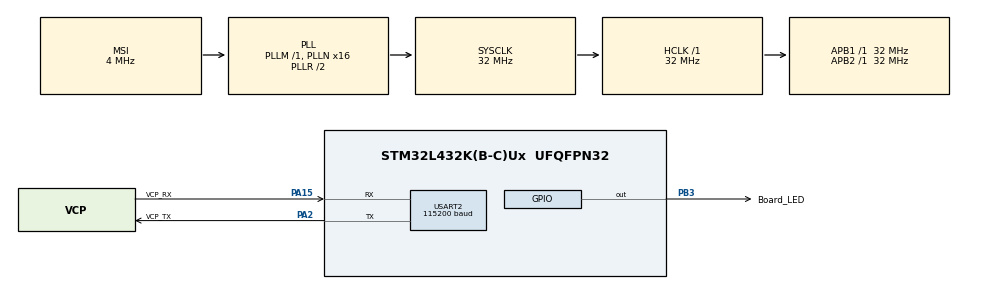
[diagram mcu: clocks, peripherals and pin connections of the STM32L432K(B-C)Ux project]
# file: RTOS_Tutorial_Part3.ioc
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FREERTOS.Tasks01=UART_task,24,128,UARTThread,Default,NULL,Dynamic,NULL,NULL;blinkLED_task,24,128,BlinkLED,Default,NULL,Dynamic,NULL,NULL
FREERTOS.configUSE_NEWLIB_REENTRANT=1
Mcu.Family=STM32L4
Mcu.Name=STM32L432K(B-C)Ux
Mcu.Package=UFQFPN32
NVIC.PriorityGroup=NVIC_PRIORITYGROUP_4
NVIC.TIM6_DAC_IRQn=true\:15\:0\:false\:false\:true\:false\:false\:true\:true
NVIC.TimeBase=TIM6_DAC_IRQn
NVIC.TimeBaseIP=TIM6
PA0.GPIO_Label=MCO [High speed clock in]
PA0.Mode=HSE-External-Clock-Source-for-LittleOrca
PA0.Signal=RCC_CK_IN
PA13\ (JTMS-SWDIO).GPIO_Label=SWDIO
PA13\ (JTMS-SWDIO).Mode=Serial_Wire
PA13\ (JTMS-SWDIO).Signal=SYS_JTMS-SWDIO
PA14\ (JTCK-SWCLK).GPIO_Label=SWCLK
PA14\ (JTCK-SWCLK).Mode=Serial_Wire
PA14\ (JTCK-SWCLK).Signal=SYS_JTCK-SWCLK
PA15\ (JTDI).GPIO_Label=VCP_RX
PA15\ (JTDI).Mode=Asynchronous
PA15\ (JTDI).Signal=USART2_RX
PA2.GPIO_Label=VCP_TX
PA2.Mode=Asynchronous
PA2.Signal=USART2_TX
PB3\ (JTDO-TRACESWO).GPIO_Label=Board_LED
PB3\ (JTDO-TRACESWO).Signal=GPIO_Output
PC14-OSC32_IN\ (PC14).Mode=LSE-External-Oscillator
PC14-OSC32_IN\ (PC14).Signal=RCC_OSC32_IN
PC15-OSC32_OUT\ (PC15).Mode=LSE-External-Oscillator
PC15-OSC32_OUT\ (PC15).Signal=RCC_OSC32_OUT
ProjectManager.HeapSize=0x200
ProjectManager.StackSize=0x400
ProjectManager.TargetToolchain=STM32CubeIDE
RCC.AHBFreq_Value=32000000
RCC.APB1Freq_Value=32000000
RCC.APB1TimFreq_Value=32000000
RCC.APB2Freq_Value=32000000
RCC.APB2TimFreq_Value=32000000
RCC.CortexFreq_Value=32000000
RCC.HCLKFreq_Value=32000000
RCC.HSE_VALUE=8000000
RCC.HSI16_VALUE=16000000
RCC.HSI48_VALUE=48000000
RCC.HSI_VALUE=16000000
RCC.MSI_VALUE=4000000
RCC.PLLMUL=RCC_PLLMUL_4
RCC.PLLN=16
RCC.SYSCLKFreq_VALUE=32000000
RCC.SYSCLKSource=RCC_SYSCLKSOURCE_PLLCLK
RCC.VCOOutputFreq_Value=64000000
USART2.BaudRate=115200
USART2.VirtualMode-Asynchronous=VM_ASYNC
VP_FREERTOS_VS_CMSIS_V2.Mode=CMSIS_V2
VP_SYS_VS_tim6.Mode=TIM6
board=NUCLEO-L432KC

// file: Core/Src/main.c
/* USER CODE BEGIN Header */
/**
  ******************************************************************************
  * @file           : main.c
  * @brief          : Main program body
  ******************************************************************************
  * @attention
  *
  * Copyright (c) 2023 STMicroelectronics.
  * All rights reserved.
  *
  * This software is licensed under terms that can be found in the LICENSE file
  * in the root directory of this software component.
  * If no LICENSE file comes with this software, it is provided AS-IS.
  *
  ******************************************************************************
  */
/* USER CODE END Header */
#include "main.h"
#include "cmsis_os.h"
#include "usart.h"
#include "gpio.h"

void SystemClock_Config(void);
void MX_FREERTOS_Init(void);

int main(void)
{

  /* MCU Configuration--------------------------------------------------------*/

  /* Reset of all peripherals, Initializes the Flash interface and the Systick. */
  HAL_Init();

  /* Configure the system clock */
  SystemClock_Config();

  /* Initialize all configured peripherals */
  MX_GPIO_Init();
  MX_USART2_UART_Init();

  /* Init scheduler */
  osKernelInitialize();  /* Call init function for freertos objects (in freertos.c) */
  MX_FREERTOS_Init();

  /* Start scheduler */
  osKernelStart();

  /* We should never get here as control is now taken by the scheduler */
  /* Infinite loop */
  while (1)
  {

  }
}

void SystemClock_Config(void)
{
  RCC_OscInitTypeDef RCC_OscInitStruct = {0};
  RCC_ClkInitTypeDef RCC_ClkInitStruct = {0};

  /** Configure the main internal regulator output voltage
  */
  if (HAL_PWREx_ControlVoltageScaling(PWR_REGULATOR_VOLTAGE_SCALE1) != HAL_OK)
  {
    Error_Handler();
  }

  /** Configure LSE Drive Capability
  */
  HAL_PWR_EnableBkUpAccess();
  __HAL_RCC_LSEDRIVE_CONFIG(RCC_LSEDRIVE_LOW);

  /** Initializes the RCC Oscillators according to the specified parameters
  * in the RCC_OscInitTypeDef structure.
  */
  RCC_OscInitStruct.OscillatorType = RCC_OSCILLATORTYPE_LSE|RCC_OSCILLATORTYPE_MSI;
  RCC_OscInitStruct.LSEState = RCC_LSE_ON;
  RCC_OscInitStruct.MSIState = RCC_MSI_ON;
  RCC_OscInitStruct.MSICalibrationValue = 0;
  RCC_OscInitStruct.MSIClockRange = RCC_MSIRANGE_6;
  RCC_OscInitStruct.PLL.PLLState = RCC_PLL_ON;
  RCC_OscInitStruct.PLL.PLLSource = RCC_PLLSOURCE_MSI;
  RCC_OscInitStruct.PLL.PLLM = 1;
  RCC_OscInitStruct.PLL.PLLN = 16;
  RCC_OscInitStruct.PLL.PLLP = RCC_PLLP_DIV7;
  RCC_OscInitStruct.PLL.PLLQ = RCC_PLLQ_DIV2;
  RCC_OscInitStruct.PLL.PLLR = RCC_PLLR_DIV2;
  if (HAL_RCC_OscConfig(&RCC_OscInitStruct) != HAL_OK)
  {
    Error_Handler();
  }

  /** Initializes the CPU, AHB and APB buses clocks
  */
  RCC_ClkInitStruct.ClockType = RCC_CLOCKTYPE_HCLK|RCC_CLOCKTYPE_SYSCLK
                              |RCC_CLOCKTYPE_PCLK1|RCC_CLOCKTYPE_PCLK2;
  RCC_ClkInitStruct.SYSCLKSource = RCC_SYSCLKSOURCE_PLLCLK;
  RCC_ClkInitStruct.AHBCLKDivider = RCC_SYSCLK_DIV1;
  RCC_ClkInitStruct.APB1CLKDivider = RCC_HCLK_DIV1;
  RCC_ClkInitStruct.APB2CLKDivider = RCC_HCLK_DIV1;

  if (HAL_RCC_ClockConfig(&RCC_ClkInitStruct, FLASH_LATENCY_1) != HAL_OK)
  {
    Error_Handler();
  }

  /** Enable MSI Auto calibration
  */
  HAL_RCCEx_EnableMSIPLLMode();
}

/* USER CODE BEGIN 4 */

int foo(int this) {
	return this;
}
/* USER CODE END 4 */

void HAL_TIM_PeriodElapsedCallback(TIM_HandleTypeDef *htim)
{
  if (htim->Instance == TIM6) {
    HAL_IncTick();
  }
}

void Error_Handler(void)
{
  __disable_irq();
  while (1)
  {
  }
}

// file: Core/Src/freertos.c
/* USER CODE BEGIN Header */
/**
  ******************************************************************************
  * File Name          : freertos.c
  * Description        : Code for freertos applications
  ******************************************************************************
  * @attention
  *
  * Copyright (c) 2023 STMicroelectronics.
  * All rights reserved.
  *
  * This software is licensed under terms that can be found in the LICENSE file
  * in the root directory of this software component.
  * If no LICENSE file comes with this software, it is provided AS-IS.
  *
  ******************************************************************************
  */
/* USER CODE END Header */

#include "FreeRTOS.h"
#include "task.h"
#include "main.h"
#include "cmsis_os.h"

/* USER CODE BEGIN Includes */
#include "usart.h"
#include <stdio.h>
#include <stdlib.h>
#include <string.h>
#include <ctype.h>
/* USER CODE END Includes */

/* USER CODE BEGIN PM */
#define UART_RX_BUFFER_SIZE			6
#define UART_TX_BUFFER_SIZE			255
#define UART_MAX_DELAY				5000
/* USER CODE END PM */

/* USER CODE BEGIN Variables */
static uint16_t ledDelay = 500;

/* USER CODE END Variables */
/* Definitions for UART_task */
osThreadId_t UART_taskHandle;
const osThreadAttr_t UART_task_attributes = {
  .name = "UART_task",
  .stack_size = 128 * 4,
  .priority = (osPriority_t) osPriorityNormal,
};
/* Definitions for blinkLED_task */
osThreadId_t blinkLED_taskHandle;
const osThreadAttr_t blinkLED_task_attributes = {
  .name = "blinkLED_task",
  .stack_size = 128 * 4,
  .priority = (osPriority_t) osPriorityNormal1,
};

void UARTThread(void *argument);
void BlinkLED(void *argument);

void MX_FREERTOS_Init(void); /* (MISRA C 2004 rule 8.1) */

void MX_FREERTOS_Init(void) {

  /* Create the thread(s) */
  /* creation of UART_task */
  UART_taskHandle = osThreadNew(UARTThread, NULL, &UART_task_attributes);

  /* creation of blinkLED_task */
  blinkLED_taskHandle = osThreadNew(BlinkLED, NULL, &blinkLED_task_attributes);

}

void UARTThread(void *argument)
{
  /* USER CODE BEGIN UARTThread */
  /* Infinite loop */
	char txBuffer[UART_TX_BUFFER_SIZE] = "Running RTOS on STM32...\r\nEnter LED Delay (0 - 65535):\r\n";
	HAL_UART_Transmit(&huart2, (uint8_t*)txBuffer, strlen(txBuffer), UART_MAX_DELAY);
	char rxBuffer[UART_RX_BUFFER_SIZE] = "";
	uint8_t rxByte;
	uint8_t rxIndex = 0;
	unsigned int tmpDelay = 0;
	for(;;)
	{
	  HAL_UART_Receive(&huart2, &rxByte, 1, HAL_MAX_DELAY);
	  if((char)rxByte == '\r') {
		  // Suspend blinking Thread, so we can change delay without Interruption
		  osThreadSuspend(blinkLED_taskHandle);
		  // Convert integer
		  tmpDelay = atoi((char*)rxBuffer);
		  if(tmpDelay > 0xFFFF) {
			  ledDelay = 0xFFFF;
		  } else {
			  ledDelay = tmpDelay;
		  }
		  sprintf(txBuffer, "Changed LED delay to: %u\r\nEnter LED Delay (0 - 65535):\r\n", ledDelay);
		  HAL_UART_Transmit(&huart2, (uint8_t*)txBuffer, strlen(txBuffer), UART_MAX_DELAY);
		  // Reset all memory for new input
		  memset(rxBuffer, 0, UART_RX_BUFFER_SIZE);
		  rxIndex = 0;
		  tmpDelay = 0;
		  // Resume blinking Thread, effectively restarting it, so it immediately picks up the new delay.
		  osThreadResume(blinkLED_taskHandle);
	  }
	  if(isdigit(rxByte)) {
		  // Ignore all characters that are not digits.
		  rxBuffer[rxIndex] = rxByte;
		  rxIndex++;
		  if(rxIndex == UART_RX_BUFFER_SIZE) {
			  sprintf(txBuffer, "Too many Digits!\r\nRe-enter number (0 - 65535):\r\n");
			  HAL_UART_Transmit(&huart2, (uint8_t*)txBuffer, strlen(txBuffer), UART_MAX_DELAY);
			  memset(rxBuffer, 0, UART_RX_BUFFER_SIZE);
			  rxIndex = 0;
		  }
	  }
	}
  /* USER CODE END UARTThread */
}

void BlinkLED(void *argument)
{
  /* USER CODE BEGIN BlinkLED */
  /* Infinite loop */
	uint16_t current_delay;
  for(;;)
  {
	  current_delay = ledDelay;
	  HAL_GPIO_TogglePin(Board_LED_GPIO_Port, Board_LED_Pin);
	  osDelay(current_delay);
  }
  /* USER CODE END BlinkLED */
}
